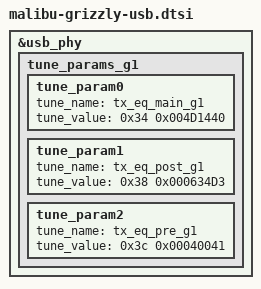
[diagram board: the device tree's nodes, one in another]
// SPDX-License-Identifier: GPL-2.0-only
/*
 * USB device tree for Grizzly
 *
 * Copyright 2025 Google LLC
 *
 */

&usb_phy {
	tune_params_g1 {
		/*
		 * Note:
		 * The following override are effective only when USB3 Gen1 is active.
		 *
		 * tune_value = <offset value>
		 */
		tune_param0 {
			tune_name = "tx_eq_main_g1";
			tune_value = <0x34 0x004D1440>;
		};
		tune_param1 {
			tune_name = "tx_eq_post_g1";
			tune_value = <0x38 0x000634D3>;
		};
		tune_param2 {
			tune_name = "tx_eq_pre_g1";
			tune_value = <0x3c 0x00040041>;
		};
	};
};
